# CY8C5888LTI_LP097 register map
File version: 0.1
Registers are 8-bit, read-write, no defined reset value unless marked. A register's access mark holds for its fields unless they carry their own. Offsets are from the block's base; [hi:lo] are bit positions; 'fields as' and 'values as' point back to an identical list.

## Timer_Right
Base 0x00000000
0x40006402 Timer_Right_COUNTER 16-bit — UDB.A0 - Current Down Counter Value
0x40006422 Timer_Right_PERIOD 16-bit — UDB.D0 - Assigned Period
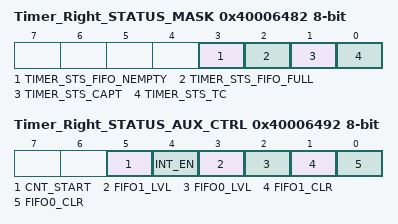
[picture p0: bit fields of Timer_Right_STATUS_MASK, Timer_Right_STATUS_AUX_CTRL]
0x40006482 Timer_Right_STATUS_MASK — UDB Status bits Interrupt Mask Enable Register
  [3] TIMER_STS_FIFO_NEMPTY ro — FIFO Empty status
  [2] TIMER_STS_FIFO_FULL ro — FIFO Full Status
  [1] TIMER_STS_CAPT ro — Enables the Interrupt on Capture
  [0] TIMER_STS_TC ro — Enables the Interrupt on TC
0x40006492 Timer_Right_STATUS_AUX_CTRL — UDB Auxilliary Control Register
  [5] CNT_START — FIFO0 clear
    0=E_CNT_START0 (Disable counter); 1=E_CNT_START1 (Enable counter)
  [4] INT_EN
    0=E_INT_EN0 (Interrupt disabled); 1=E_INT_EN1 (Interrupt enabled)
  [3] FIFO1_LVL — FIFO level
    0=E_FIFO_LVL_0 (FIFO LVL: input mode: FIFO not full; output mode: FIFO not empty); 1=E_FIFO_LVL_1 (FIFO LVL: input mode: FIFO at least 1/2 empty; output mode: FIFO at least 1/2 full)
  [2] FIFO0_LVL — FIFO level
    values as FIFO1_LVL
  [1] FIFO1_CLR — FIFO1 clear
    0=E_FIFO_CLR_0 (Normal FIFO operation); 1=E_FIFO_CLR_1 (Clear FIFO state)
  [0] FIFO0_CLR — FIFO0 clear
    values as FIFO1_CLR

## PWM_Servo_D
Base 0x00000000
0x40006421 PWM_Servo_D_COMPARE_Reg_ — UDB.D0 - Assigned Compare Value
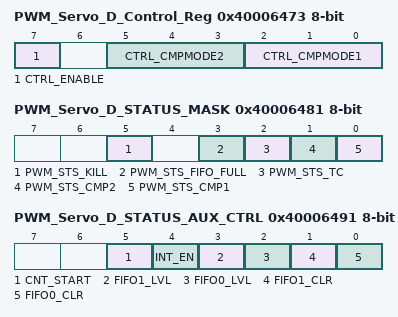
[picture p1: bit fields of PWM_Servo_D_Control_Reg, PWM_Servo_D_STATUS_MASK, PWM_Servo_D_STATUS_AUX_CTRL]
0x40006473 PWM_Servo_D_Control_Reg — UDB Control Register - Assigned Control Register Value
  [7] CTRL_ENABLE — Enable the PWM
  [5:3] CTRL_CMPMODE2 — Compare mode 2
  [2:0] CTRL_CMPMODE1 — Compare mode 1
0x40006481 PWM_Servo_D_STATUS_MASK — UDB Status bits Interrupt Mask Enable Register
  [5] PWM_STS_KILL ro — Enables the Interrupt on Kill
  [3] PWM_STS_FIFO_FULL ro — FIFO Full Status Mask
  [2] PWM_STS_TC ro — Enables the Interrupt on Terminal Count
  [1] PWM_STS_CMP2 ro — Enables the Interrupt on Compare 2
  [0] PWM_STS_CMP1 ro — Enables the Interrupt on Compare 1
0x40006491 PWM_Servo_D_STATUS_AUX_CTRL — UDB Auxilliary Control Register
  [5] CNT_START — FIFO0 clear
    0=E_CNT_START0 (Disable counter); 1=E_CNT_START1 (Enable counter)
  [4] INT_EN
    0=E_INT_EN0 (Interrupt disabled); 1=E_INT_EN1 (Interrupt enabled)
  [3] FIFO1_LVL — FIFO level
    0=E_FIFO_LVL_0 (FIFO LVL: input mode: FIFO not full; output mode: FIFO not empty); 1=E_FIFO_LVL_1 (FIFO LVL: input mode: FIFO at least 1/2 empty; output mode: FIFO at least 1/2 full)
  [2] FIFO0_LVL — FIFO level
    values as FIFO1_LVL
  [1] FIFO1_CLR — FIFO1 clear
    0=E_FIFO_CLR_0 (Normal FIFO operation); 1=E_FIFO_CLR_1 (Clear FIFO state)
  [0] FIFO0_CLR — FIFO0 clear
    values as FIFO1_CLR

## PWM_Servo_C
Base 0x00000000
0x40006420 PWM_Servo_C_COMPARE_Reg_ — UDB.D0 - Assigned Compare Value
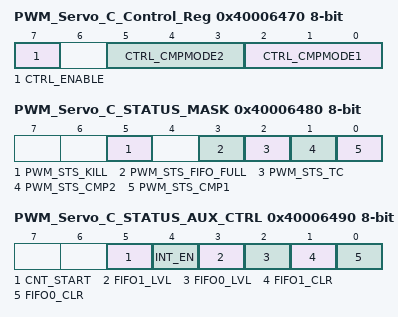
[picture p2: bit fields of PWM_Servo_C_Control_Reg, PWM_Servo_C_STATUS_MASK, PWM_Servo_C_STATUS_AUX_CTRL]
0x40006470 PWM_Servo_C_Control_Reg — UDB Control Register - Assigned Control Register Value
  [7] CTRL_ENABLE — Enable the PWM
  [5:3] CTRL_CMPMODE2 — Compare mode 2
  [2:0] CTRL_CMPMODE1 — Compare mode 1
0x40006480 PWM_Servo_C_STATUS_MASK — UDB Status bits Interrupt Mask Enable Register
  [5] PWM_STS_KILL ro — Enables the Interrupt on Kill
  [3] PWM_STS_FIFO_FULL ro — FIFO Full Status Mask
  [2] PWM_STS_TC ro — Enables the Interrupt on Terminal Count
  [1] PWM_STS_CMP2 ro — Enables the Interrupt on Compare 2
  [0] PWM_STS_CMP1 ro — Enables the Interrupt on Compare 1
0x40006490 PWM_Servo_C_STATUS_AUX_CTRL — UDB Auxilliary Control Register
  [5] CNT_START — FIFO0 clear
    0=E_CNT_START0 (Disable counter); 1=E_CNT_START1 (Enable counter)
  [4] INT_EN
    0=E_INT_EN0 (Interrupt disabled); 1=E_INT_EN1 (Interrupt enabled)
  [3] FIFO1_LVL — FIFO level
    0=E_FIFO_LVL_0 (FIFO LVL: input mode: FIFO not full; output mode: FIFO not empty); 1=E_FIFO_LVL_1 (FIFO LVL: input mode: FIFO at least 1/2 empty; output mode: FIFO at least 1/2 full)
  [2] FIFO0_LVL — FIFO level
    values as FIFO1_LVL
  [1] FIFO1_CLR — FIFO1 clear
    0=E_FIFO_CLR_0 (Normal FIFO operation); 1=E_FIFO_CLR_1 (Clear FIFO state)
  [0] FIFO0_CLR — FIFO0 clear
    values as FIFO1_CLR
